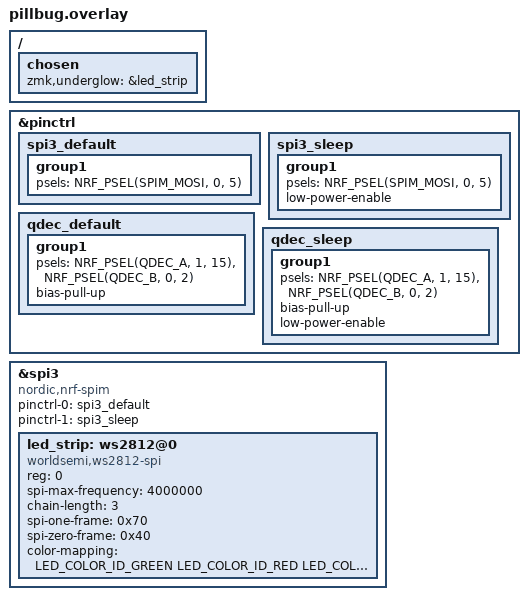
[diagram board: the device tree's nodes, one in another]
#include <dt-bindings/led/led.h>

&pinctrl {
    spi3_default: spi3_default {
        group1 {
            psels = <NRF_PSEL(SPIM_MOSI, 0, 5)>;
        };
    };

    spi3_sleep: spi3_sleep {
        group1 {
            psels = <NRF_PSEL(SPIM_MOSI, 0, 5)>;
            low-power-enable;
        };
    };

    qdec_default: qdec_default {
        group1 {
            psels = <NRF_PSEL(QDEC_A, 1, 15)>,
                    <NRF_PSEL(QDEC_B, 0, 2)>;
            bias-pull-up;
        };
    };

    qdec_sleep: qdec_sleep {
        group1 {
            psels = <NRF_PSEL(QDEC_A, 1, 15)>,
                    <NRF_PSEL(QDEC_B, 0, 2)>;
            bias-pull-up; // TODO: find out if this makes sense with low-power-enable
            low-power-enable;
        };
    };
};

&spi3 {
    compatible = "nordic,nrf-spim";
    status = "okay";

    pinctrl-0 = <&spi3_default>;
    pinctrl-1 = <&spi3_sleep>;
    pinctrl-names = "default", "sleep";

    led_strip: ws2812@0 {
        compatible = "worldsemi,ws2812-spi";

        /* SPI */
        reg = <0>; /* ignored, but necessary for SPI bindings */
        spi-max-frequency = <4000000>;

        /* WS2812 */
        chain-length = <3>;
        spi-one-frame = <0x70>;
        spi-zero-frame = <0x40>;

        color-mapping = <LED_COLOR_ID_GREEN LED_COLOR_ID_RED LED_COLOR_ID_BLUE>;
    };
};

/ {
    chosen {
        zmk,underglow = &led_strip;
    };
};

/*
 * You have the option to use the nRF QDEC driver for the encoder. Commented out by default because in all tests so far with the hardware provided by MechWild, the QDEC driver has resulted in poorer performance (more skips) than the default GPIO-based driver.
 */

/*
/ {
    /delete-node/ encoder_0;
};

encoder: &qdec0 {
    status = "disabled";
    led-pre = <0>;
    steps = <80>;
    pinctrl-0 = <&qdec_default>;
    pinctrl-1 = <&qdec_sleep>;
    pinctrl-names = "default", "sleep";
};
*/
